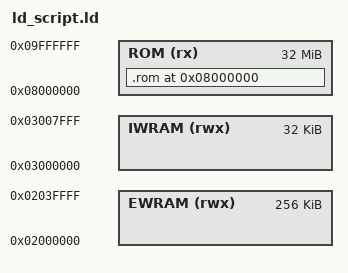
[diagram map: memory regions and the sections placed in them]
OUTPUT_ARCH(arm)
ENTRY(crt0_start)

MEMORY
{
    EWRAM (rwx) : ORIGIN = 0x2000000, LENGTH = 256K
    IWRAM (rwx) : ORIGIN = 0x3000000, LENGTH = 32K
    ROM    (rx) : ORIGIN = 0x8000000, LENGTH = 32M
}

INCLUDE symbols.ld

SECTIONS {
    . = 0x8000000;

    .rom 0x8000000 :
    ALIGN(4)
    {
        build/asm/crt0.o(.text);
        build/src/engine/main.o(.text);
        build/src/engine/main.o(.rodata);
        build/src/engine/decompress.o(.text);
        build/src/engine/decompress.o(.rodata);
        build/src/engine/bg.o(.text);
        build/src/engine/bg.o(.rodata);
        build/src/engine/math.o(.text);
        build/src/engine/math.o(.rodata);
        build/src/engine/palette.o(.text);
        build/src/engine/palette.o(.rodata);
        build/src/engine/oam.o(.text);
        build/src/engine/oam.o(.rodata);
        build/src/link/serial.o(.text);
        build/src/link/serial.o(.rodata);
        build/src/engine/game_state.o(.text);
        build/src/engine/game_state.o(.rodata);
        build/src/menu/field_menu.o(.text);
        build/src/menu/field_menu.o(.rodata);
        build/src/menu/medawatch_menu.o(.text);
        build/src/menu/medawatch_menu.o(.rodata);
        build/src/menu/medabots_screen.o(.text);
        build/src/menu/medabots_screen.o(.rodata);
        build/src/menu/medals_screen.o(.text);
        build/src/menu/medals_screen.o(.rodata);
        build/src/debug/debug_menu.o(.text);
        build/src/debug/debug_menu.o(.rodata);
        build/src/menu/medaparts_screen.o(.text);
        build/src/menu/medaparts_screen.o(.rodata);
        build/src/battle/prebattle.o(.text);
        build/src/battle/prebattle.o(.rodata);
        build/src/battle/robattle.o(.text);
        build/src/battle/robattle.o(.rodata);
        build/src/battle/battle_bots.o(.text);
        build/src/battle/battle_bots.o(.rodata);
        build/src/battle/battle_hud.o(.text);
        build/src/battle/battle_hud.o(.rodata);
        build/src/battle/command_ring.o(.text);
        build/src/battle/command_ring.o(.rodata);
        build/src/battle/part_select.o(.text);
        build/src/battle/part_select.o(.rodata);
        build/src/battle/medaforce_select.o(.text);
        build/src/battle/medaforce_select.o(.rodata);
        build/src/battle/status_screen.o(.text);
        build/src/battle/status_screen.o(.rodata);
        build/src/battle/battle_setup.o(.text);
        build/src/battle/battle_setup.o(.rodata);
        build/src/battle/robattle_timer.o(.text);
        build/src/battle/robattle_timer.o(.rodata);
        build/src/battle/part_stats.o(.text);
        build/src/battle/part_stats.o(.rodata);
        build/src/battle/bot_movement.o(.text);
        build/src/battle/bot_movement.o(.rodata);
        build/src/battle/status_sprites.o(.text);
        build/src/battle/status_sprites.o(.rodata);
        build/src/battle/action_queue.o(.text);
        build/src/battle/action_queue.o(.rodata);
        build/src/battle/battle_graphics.o(.text);
        build/src/battle/battle_graphics.o(.rodata);
        build/src/battle/turn_order.o(.text);
        build/src/battle/turn_order.o(.rodata);
        build/src/battle/battle_sprites.o(.text);
        build/src/battle/battle_sprites.o(.rodata);
        build/src/battle/action_steps.o(.text);
        build/src/battle/action_steps.o(.rodata);
        build/src/battle/defend_heal_skills.o(.text);
        build/src/battle/defend_heal_skills.o(.rodata);
        build/src/battle/support_skills.o(.text);
        build/src/battle/support_skills.o(.rodata);
        build/src/battle/interrupt_skills.o(.text);
        build/src/battle/interrupt_skills.o(.rodata);
        build/src/battle/medaforce_effects.o(.text);
        build/src/battle/medaforce_effects.o(.rodata);
        build/src/battle/effect_steps.o(.text);
        build/src/battle/effect_steps.o(.rodata);
        build/src/battle/action_phase.o(.text);
        build/src/battle/action_phase.o(.rodata);
        build/src/battle/battle_ai.o(.text);
        build/src/battle/battle_ai.o(.rodata);
        build/src/battle/action_script.o(.text);
        build/src/battle/action_script.o(.rodata);
        build/src/battle/combat_helpers.o(.text);
        build/src/battle/combat_helpers.o(.rodata);
        build/src/battle/closeup_scene.o(.text);
        build/src/battle/closeup_scene.o(.rodata);
        build/src/battle/effect_sprites.o(.text);
        build/src/battle/effect_sprites.o(.rodata);
        build/src/battle/skill_helpers.o(.text);
        build/src/battle/skill_helpers.o(.rodata);
        build/src/battle/particles.o(.text);
        build/src/battle/particles.o(.rodata);
        build/src/battle/action_calc.o(.text);
        build/src/battle/action_calc.o(.rodata);
        build/src/battle/battle_sequence.o(.text);
        build/src/battle/battle_sequence.o(.rodata);
        build/src/link/link_robattle.o(.text);
        build/src/link/link_robattle.o(.rodata);
        build/src/engine/tilemap.o(.text);
        build/src/engine/tilemap.o(.rodata);
        build/src/engine/memory.o(.text);
        build/src/engine/memory.o(.rodata);
        build/src/engine/palette_blend.o(.text);
        build/src/engine/palette_blend.o(.rodata);
        build/src/text/message.o(.text);
        build/src/text/message.o(.rodata);
        build/src/engine/sprites.o(.text);
        build/src/engine/sprites.o(.rodata);
        build/src/text/choice_menu.o(.text);
        build/src/text/choice_menu.o(.rodata);
        build/src/inventory/inventory.o(.text);
        build/src/inventory/inventory.o(.rodata);
        build/src/engine/common.o(.text);
        build/src/engine/common.o(.rodata);
        build/src/engine/sprite_engine.o(.text);
        build/src/engine/sprite_engine.o(.rodata);
        build/src/engine/interpolate.o(.text);
        build/src/engine/interpolate.o(.rodata);
        build/src/field/field_mode.o(.text);
        build/src/field/field_mode.o(.rodata);
        build/src/field/script_helpers.o(.text);
        build/src/field/script_helpers.o(.rodata);
        build/src/field/area_graphics.o(.text);
        build/src/field/area_graphics.o(.rodata);
        build/src/field/field_utils.o(.text);
        build/src/field/field_utils.o(.rodata);
        build/src/field/field_effects.o(.text);
        build/src/field/field_effects.o(.rodata);
        build/src/field/field_update.o(.text);
        build/src/field/field_update.o(.rodata);
        build/src/field/map_script.o(.text);
        build/src/field/map_script.o(.rodata);
        build/src/field/map_script_update.o(.text);
        build/src/field/map_script_update.o(.rodata);
        build/src/field/script_sprites.o(.text);
        build/src/field/script_sprites.o(.rodata);
        build/src/field/field_walk.o(.text);
        build/src/field/field_walk.o(.rodata);
        build/src/field/player_walk.o(.text);
        build/src/field/player_walk.o(.rodata);
        build/src/field/map_objects.o(.text);
        build/src/field/map_objects.o(.rodata);
        build/src/field/scene_3d.o(.text);
        build/src/field/scene_3d.o(.rodata);
        build/src/field/vehicle_menu.o(.text);
        build/src/field/vehicle_menu.o(.rodata);
        build/src/field/field_debug.o(.text);
        build/src/field/field_debug.o(.rodata);
        build/src/engine/bg_draw.o(.text);
        build/src/engine/bg_draw.o(.rodata);
        build/src/menu/item_list.o(.text);
        build/src/menu/item_list.o(.rodata);
        build/src/title/screen_helpers.o(.text);
        build/src/title/screen_helpers.o(.rodata);
        build/src/title/title_menu.o(.text);
        build/src/title/title_menu.o(.rodata);
        build/src/title/new_game_prompt.o(.text);
        build/src/title/new_game_prompt.o(.rodata);
        build/src/menu/item_menu.o(.text);
        build/src/menu/item_menu.o(.rodata);
        build/src/save/save_screen.o(.text);
        build/src/save/save_screen.o(.rodata);
        build/src/save/save_data.o(.text);
        build/src/save/save_data.o(.rodata);
        build/src/menu/name_entry.o(.text);
        build/src/menu/name_entry.o(.rodata);
        build/src/code_0805EF9C.o(.text);
        build/src/code_0805EF9C.o(.rodata);
        build/src/code_08063090.o(.text);
        build/src/code_08063090.o(.rodata);
        build/src/code_08067160.o(.text);
        build/src/code_08067160.o(.rodata);
        build/src/code_0806B160.o(.text);
        build/src/code_0806B160.o(.rodata);
        build/src/code_0806F3F0.o(.text);
        build/src/code_0806F3F0.o(.rodata);
        build/src/audio/sound_seq.o(.text);
        build/src/audio/sound_seq.o(.rodata);
        build/src/audio/sound_driver.o(.text);
        build/src/audio/sound_driver.o(.rodata);
        build/data/rodata_080750D8.o(.rodata);
        build/asm/lib/eeprom.o(.text);
        build/asm/lib/syscall.o(.text);
        build/asm/lib/call_via.o(.text);
        build/asm/lib/libgcc.o(.text);
        build/data/data_0807E6F0.o(.rodata);
        build/data/data_08080000.o(.rodata);
        build/sound/sound_data.o(.rodata);
        build/data/data_083AB9D0.o(.rodata);
        build/data/data_08480000.o(.rodata);
        build/graphics/graphics_08590000.o(.rodata);
        build/data/free_087F3270.o(.rodata);
    } > ROM =0

    /DISCARD/ :
    {
        *(.comment .note .ARM.attributes)
    }
}
